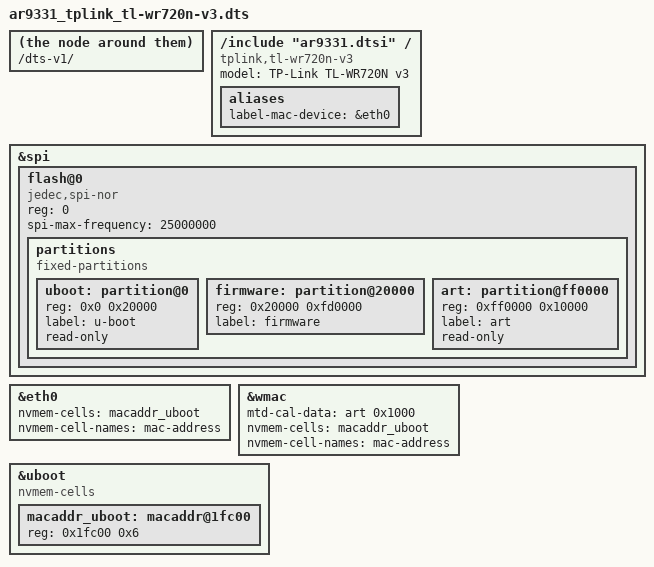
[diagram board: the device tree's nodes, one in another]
/dts-v1/;

/include "ar9331.dtsi"

/ {
    compatible = "tplink,tl-wr720n-v3", "qca,ar9331";
    model = "TP-Link TL-WR720N v3";

    aliases {
        label-mac-device = &eth0;
    };
};

&spi {
    status = "okay";

    flash@0 {
        compatible = "jedec,spi-nor";
        reg = <0>;
        spi-max-frequency = <25000000>;

        partitions {
            compatible = "fixed-partitions";
            #address-cells = <1>;
            #size-cells = <1>;

            uboot: partition@0 {
                reg = <0x0 0x20000>;
                label = "u-boot";
                read-only;
            };

            firmware: partition@20000 {
                reg = <0x20000 0xfd0000>;  // 16MB 减去 u-boot
                label = "firmware";
            };

            art: partition@ff0000 {
                reg = <0xff0000 0x10000>;
                label = "art";
                read-only;
            };
        };
    };
};

&eth0 {
    nvmem-cells = <&macaddr_uboot>;
    nvmem-cell-names = "mac-address";
};

&wmac {
    mtd-cal-data = <&art 0x1000>;
    nvmem-cells = <&macaddr_uboot>;
    nvmem-cell-names = "mac-address";
};

&uboot {
    compatible = "nvmem-cells";

    macaddr_uboot: macaddr@1fc00 {
        reg = <0x1fc00 0x6>;
    };
};
